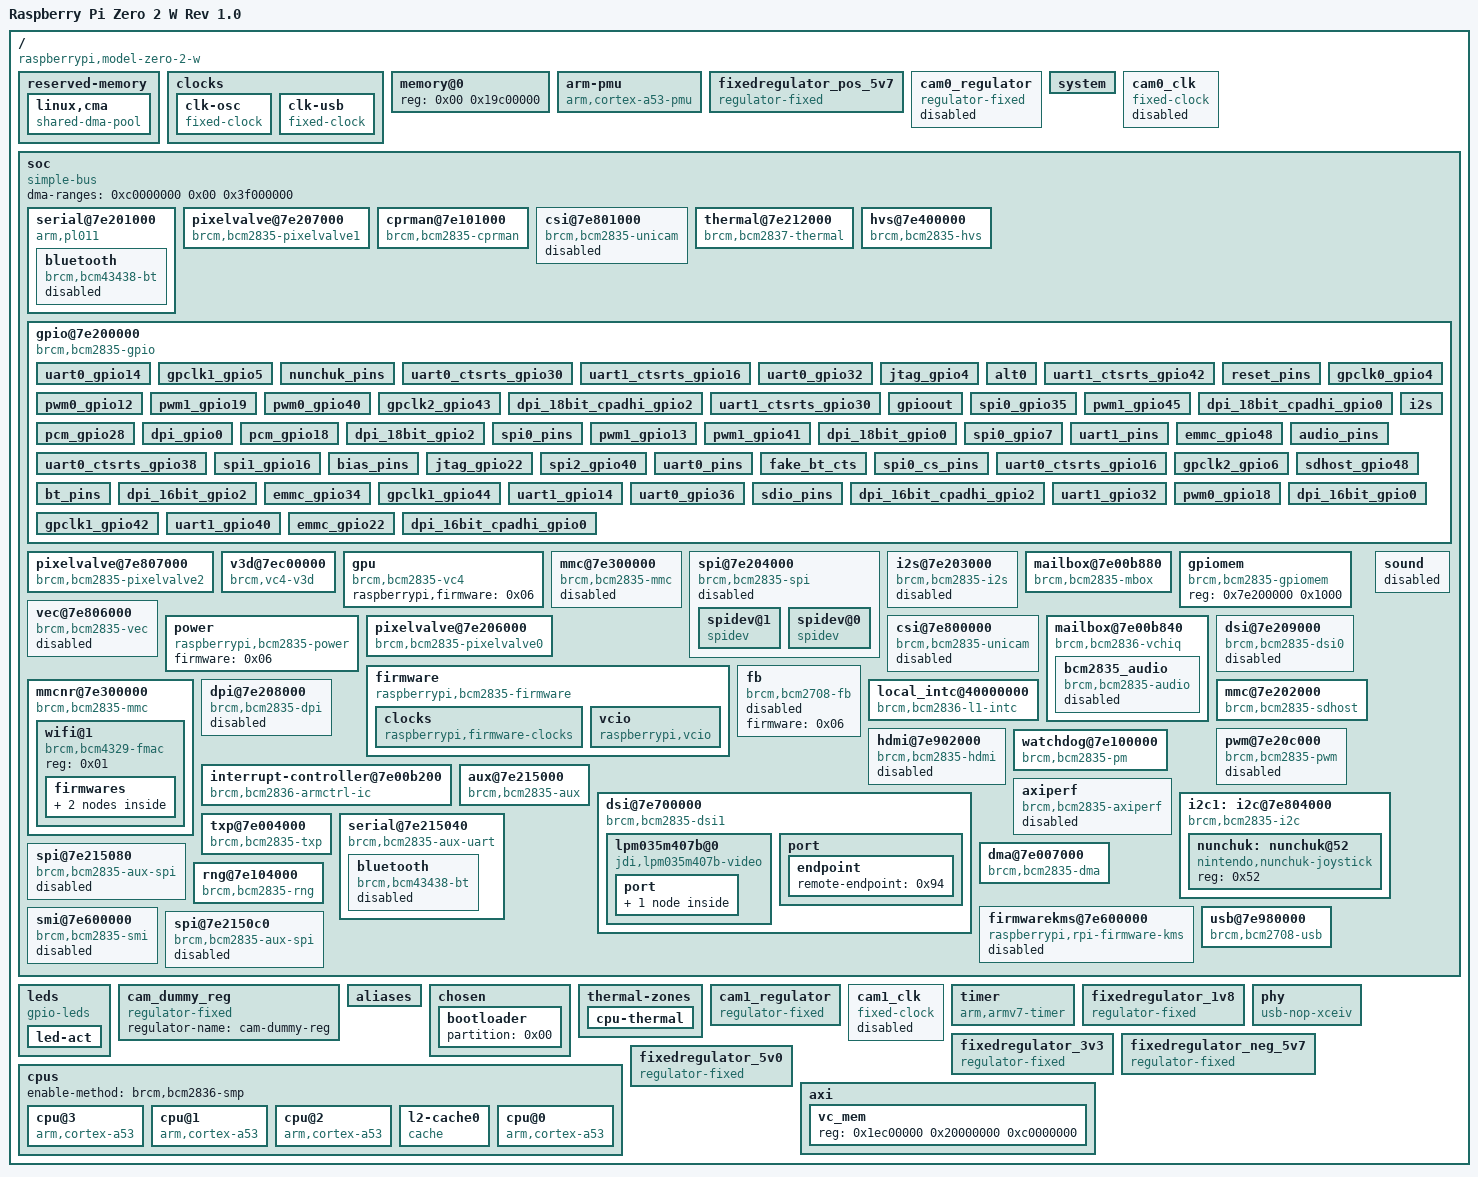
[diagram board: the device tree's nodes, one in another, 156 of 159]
/dts-v1/;

/ {
	compatible = "raspberrypi,model-zero-2-w\0brcm,bcm2837";
	serial-number = "00000000a24858e5";
	model = "Raspberry Pi Zero 2 W Rev 1.0";
	memreserve = <0x19c00000 0x6400000>;
	interrupt-parent = <0x01>;
	#address-cells = <0x01>;
	#size-cells = <0x01>;

	reserved-memory {
		ranges;
		#address-cells = <0x01>;
		#size-cells = <0x01>;
		phandle = <0x34>;

		linux,cma {
			reusable;
			compatible = "shared-dma-pool";
			size = <0x10000000>;
			phandle = <0x35>;
			linux,cma-default;
		};
	};

	clocks {

		clk-osc {
			compatible = "fixed-clock";
			#clock-cells = <0x00>;
			phandle = <0x03>;
			clock-output-names = "osc";
			clock-frequency = <0x124f800>;
		};

		clk-usb {
			compatible = "fixed-clock";
			#clock-cells = <0x00>;
			phandle = <0x18>;
			clock-output-names = "otg";
			clock-frequency = <0x1c9c3800>;
		};
	};

	memory@0 {
		device_type = "memory";
		reg = <0x00 0x19c00000>;
	};

	__overrides__ {
		cam0-led-ctrl;
		sd_overclock = "\0\0\0.brcm,overclock-50:0";
		sdio_overclock = "\0\0\0/brcm,overclock-50:0\0\0\0\00brcm,overclock-50:0";
		sd_pio_limit = "\0\0\0.brcm,pio-limit:0";
		act_led_trigger = "\0\0\03linux,default-trigger";
		audio = "\0\0\0+status";
		sd_debug = "\0\0\0.brcm,debug";
		cam0-pwdn-ctrl;
		cache_line_size;
		cam0-led;
		spi = "\0\0\0(status";
		uart0 = "\0\0\0%status";
		i2s = "\0\0\0'status";
		arm_freq = "\0\0\0!clock-frequency:0\0\0\0\0\"clock-frequency:0\0\0\0\0#clock-frequency:0\0\0\0\0$clock-frequency:0";
		watchdog = "\0\0\0,status";
		krnbt = "\0\0\02status";
		sd_poll_once = "\0\0\0.non-removable?";
		axiperf = "\0\0\01status";
		act_led_activelow = "\0\0\03gpios:8";
		krnbt_baudrate = "\0\0\02max-speed:0";
		sd_force_pio = "\0\0\0.brcm,force-pio?";
		cam0-pwdn;
		uart1 = "\0\0\0&status";
		random = "\0\0\0-status";
		act_led_gpio = "\0\0\03gpios:4";
	};

	arm-pmu {
		compatible = "arm,cortex-a53-pmu\0arm,cortex-a7-pmu";
		interrupt-parent = <0x1a>;
		interrupts = <0x09 0x04>;
	};

	fixedregulator_pos_5v7 {
		compatible = "regulator-fixed";
		enable-active-high;
		gpio = <0x07 0x18 0x00>;
		phandle = <0x96>;
		regulator-min-microvolt = <0x56f9a0>;
		regulator-max-microvolt = <0x56f9a0>;
		regulator-name = "lcm_pos_bias";
	};

	cam0_regulator {
		compatible = "regulator-fixed";
		enable-active-high;
		status = "disabled";
		phandle = <0x8a>;
		regulator-name = "cam0-reg";
	};

	system {
		linux,serial = <0x00 0xa24858e5>;
		linux,revision = <0x902120>;
	};

	__symbols__ {
		uart0_gpio14 = "/soc/gpio@7e200000/uart0_gpio14";
		pwm = "/soc/pwm@7e20c000";
		gpclk1_gpio5 = "/soc/gpio@7e200000/gpclk1_gpio5";
		clk_usb = "/clocks/clk-usb";
		pixelvalve0 = "/soc/pixelvalve@7e206000";
		minibt = "/soc/serial@7e215040/bluetooth";
		uart0_ctsrts_gpio30 = "/soc/gpio@7e200000/uart0_ctsrts_gpio30";
		uart1_ctsrts_gpio16 = "/soc/gpio@7e200000/uart1_ctsrts_gpio16";
		uart0_gpio32 = "/soc/gpio@7e200000/uart0_gpio32";
		intc = "/soc/interrupt-controller@7e00b200";
		spi2 = "/soc/spi@7e2150c0";
		jtag_gpio4 = "/soc/gpio@7e200000/jtag_gpio4";
		dsi1 = "/soc/dsi@7e700000";
		clocks = "/soc/cprman@7e101000";
		alt0 = "/soc/gpio@7e200000/alt0";
		firmwarekms = "/soc/firmwarekms@7e600000";
		smi = "/soc/smi@7e600000";
		uart1_ctsrts_gpio42 = "/soc/gpio@7e200000/uart1_ctsrts_gpio42";
		spi0 = "/soc/spi@7e204000";
		bt = "/soc/serial@7e201000/bluetooth";
		thermal = "/soc/thermal@7e212000";
		vdd_5v0_reg = "/fixedregulator_5v0";
		vchiq = "/soc/mailbox@7e00b840";
		sdhost = "/soc/mmc@7e202000";
		aux = "/soc/aux@7e215000";
		cam0_regulator = "/cam0_regulator";
		gpio = "/soc/gpio@7e200000";
		gpclk0_gpio4 = "/soc/gpio@7e200000/gpclk0_gpio4";
		pwm0_gpio12 = "/soc/gpio@7e200000/pwm0_gpio12";
		pwm1_gpio19 = "/soc/gpio@7e200000/pwm1_gpio19";
		sdhci = "/soc/mmc@7e300000";
		pwm0_gpio40 = "/soc/gpio@7e200000/pwm0_gpio40";
		gpclk2_gpio43 = "/soc/gpio@7e200000/gpclk2_gpio43";
		cam1_reg = "/cam1_regulator";
		dpi = "/soc/dpi@7e208000";
		dpi_18bit_cpadhi_gpio2 = "/soc/gpio@7e200000/dpi_18bit_cpadhi_gpio2";
		v3d = "/soc/v3d@7ec00000";
		audio = "/soc/mailbox@7e00b840/bcm2835_audio";
		vdd_3v3_reg = "/fixedregulator_3v3";
		uart1_ctsrts_gpio30 = "/soc/gpio@7e200000/uart1_ctsrts_gpio30";
		gpioout = "/soc/gpio@7e200000/gpioout";
		dma = "/soc/dma@7e007000";
		spidev1 = "/soc/spi@7e204000/spidev@1";
		mmcnr = "/soc/mmcnr@7e300000";
		spi0_gpio35 = "/soc/gpio@7e200000/spi0_gpio35";
		vc4 = "/soc/gpu";
		firmware_clocks = "/soc/firmware/clocks";
		pwm1_gpio45 = "/soc/gpio@7e200000/pwm1_gpio45";
		cpu3 = "/cpus/cpu@3";
		dpi_18bit_cpadhi_gpio0 = "/soc/gpio@7e200000/dpi_18bit_cpadhi_gpio0";
		cam0_clk = "/cam0_clk";
		pcm_gpio28 = "/soc/gpio@7e200000/pcm_gpio28";
		dpi_gpio0 = "/soc/gpio@7e200000/dpi_gpio0";
		power = "/soc/power";
		soc = "/soc";
		pcm_gpio18 = "/soc/gpio@7e200000/pcm_gpio18";
		leds = "/leds";
		csi1 = "/soc/csi@7e801000";
		i2s_pins = "/soc/gpio@7e200000/i2s";
		cam_dummy_reg = "/cam_dummy_reg";
		firmware = "/soc/firmware";
		cpu1 = "/cpus/cpu@1";
		mmc = "/soc/mmc@7e300000";
		l2 = "/cpus/l2-cache0";
		dpi_18bit_gpio2 = "/soc/gpio@7e200000/dpi_18bit_gpio2";
		usbphy = "/phy";
		pixelvalve1 = "/soc/pixelvalve@7e207000";
		spi = "/soc/spi@7e204000";
		spi0_pins = "/soc/gpio@7e200000/spi0_pins";
		clk_osc = "/clocks/clk-osc";
		uart0 = "/soc/serial@7e201000";
		pwm1_gpio13 = "/soc/gpio@7e200000/pwm1_gpio13";
		rmem = "/reserved-memory";
		cpu_thermal = "/thermal-zones/cpu-thermal";
		fb = "/soc/fb";
		pwm1_gpio41 = "/soc/gpio@7e200000/pwm1_gpio41";
		txp = "/soc/txp@7e004000";
		dpi_18bit_gpio0 = "/soc/gpio@7e200000/dpi_18bit_gpio0";
		spi0_gpio7 = "/soc/gpio@7e200000/spi0_gpio7";
		uart1_pins = "/soc/gpio@7e200000/uart1_pins";
		cma = "/reserved-memory/linux,cma";
		cam1_clk = "/cam1_clk";
		i2s = "/soc/i2s@7e203000";
		emmc_gpio48 = "/soc/gpio@7e200000/emmc_gpio48";
		spi1 = "/soc/spi@7e215080";
		usb = "/soc/usb@7e980000";
		dsi0 = "/soc/dsi@7e209000";
		uart0_ctsrts_gpio38 = "/soc/gpio@7e200000/uart0_ctsrts_gpio38";
		pm = "/soc/watchdog@7e100000";
		audio_pins = "/soc/gpio@7e200000/audio_pins";
		brcmf = "/soc/mmcnr@7e300000/wifi@1";
		spi1_gpio16 = "/soc/gpio@7e200000/spi1_gpio16";
		watchdog = "/soc/watchdog@7e100000";
		jtag_gpio22 = "/soc/gpio@7e200000/jtag_gpio22";
		spi2_gpio40 = "/soc/gpio@7e200000/spi2_gpio40";
		uart0_pins = "/soc/gpio@7e200000/uart0_pins";
		vec = "/soc/vec@7e806000";
		local_intc = "/soc/local_intc@40000000";
		axiperf = "/soc/axiperf";
		spi0_cs_pins = "/soc/gpio@7e200000/spi0_cs_pins";
		sound = "/soc/sound";
		hvs = "/soc/hvs@7e400000";
		uart0_ctsrts_gpio16 = "/soc/gpio@7e200000/uart0_ctsrts_gpio16";
		act_led = "/leds/led-act";
		gpclk2_gpio6 = "/soc/gpio@7e200000/gpclk2_gpio6";
		spidev0 = "/soc/spi@7e204000/spidev@0";
		sdhost_gpio48 = "/soc/gpio@7e200000/sdhost_gpio48";
		bt_pins = "/soc/gpio@7e200000/bt_pins";
		dpi_16bit_gpio2 = "/soc/gpio@7e200000/dpi_16bit_gpio2";
		emmc_gpio34 = "/soc/gpio@7e200000/emmc_gpio34";
		gpclk1_gpio44 = "/soc/gpio@7e200000/gpclk1_gpio44";
		uart1_gpio14 = "/soc/gpio@7e200000/uart1_gpio14";
		uart0_gpio36 = "/soc/gpio@7e200000/uart0_gpio36";
		sdio_pins = "/soc/gpio@7e200000/sdio_pins";
		dpi_16bit_cpadhi_gpio2 = "/soc/gpio@7e200000/dpi_16bit_cpadhi_gpio2";
		cpus = "/cpus";
		cpu2 = "/cpus/cpu@2";
		uart1_gpio32 = "/soc/gpio@7e200000/uart1_gpio32";
		hdmi = "/soc/hdmi@7e902000";
		pixelvalve2 = "/soc/pixelvalve@7e807000";
		pwm0_gpio18 = "/soc/gpio@7e200000/pwm0_gpio18";
		dpi_16bit_gpio0 = "/soc/gpio@7e200000/dpi_16bit_gpio0";
		gpclk1_gpio42 = "/soc/gpio@7e200000/gpclk1_gpio42";
		mailbox = "/soc/mailbox@7e00b880";
		uart1_gpio40 = "/soc/gpio@7e200000/uart1_gpio40";
		emmc_gpio22 = "/soc/gpio@7e200000/emmc_gpio22";
		uart1 = "/soc/serial@7e215040";
		dpi_16bit_cpadhi_gpio0 = "/soc/gpio@7e200000/dpi_16bit_cpadhi_gpio0";
		csi0 = "/soc/csi@7e800000";
		cam0_reg = "/cam_dummy_reg";
		random = "/soc/rng@7e104000";
		cpu0 = "/cpus/cpu@0";
		vcio = "/soc/firmware/vcio";
	};

	cam0_clk {
		compatible = "fixed-clock";
		status = "disabled";
		#clock-cells = <0x00>;
		phandle = <0x8b>;
	};

	soc {
		compatible = "simple-bus";
		ranges = <0x7e000000 0x3f000000 0x1000000 0x40000000 0x40000000 0x1000>;
		#address-cells = <0x01>;
		#size-cells = <0x01>;
		phandle = <0x37>;
		dma-ranges = <0xc0000000 0x00 0x3f000000>;

		serial@7e201000 {
			compatible = "arm,pl011\0arm,primecell";
			clocks = <0x08 0x13 0x08 0x14>;
			clock-names = "uartclk\0apb_pclk";
			status = "okay";
			interrupts = <0x02 0x19>;
			skip-init;
			phandle = <0x25>;
			arm,primecell-periphid = <0x241011>;
			reg = <0x7e201000 0x200>;
			pinctrl-0 = <0x09>;
			cts-event-workaround;
			pinctrl-names = "default";

			bluetooth {
				compatible = "brcm,bcm43438-bt";
				shutdown-gpios = <0x07 0x2a 0x00>;
				max-speed = <0x2dc6c0>;
				status = "disabled";
				phandle = <0x32>;
			};
		};

		pixelvalve@7e207000 {
			compatible = "brcm,bcm2835-pixelvalve1";
			status = "okay";
			interrupts = <0x02 0x0e>;
			phandle = <0x78>;
			reg = <0x7e207000 0x100>;
		};

		cprman@7e101000 {
			compatible = "brcm,bcm2835-cprman";
			clocks = <0x03 0x04 0x00 0x04 0x01 0x04 0x02 0x05 0x00 0x05 0x01 0x05 0x02>;
			firmware = <0x06>;
			#clock-cells = <0x01>;
			phandle = <0x08>;
			claim-clocks = <0x22 0x23 0x0f 0x10>;
			reg = <0x7e101000 0x2000>;
		};

		csi@7e801000 {
			power-domains = <0x13 0x0d>;
			compatible = "brcm,bcm2835-unicam";
			clocks = <0x08 0x2e 0x1b 0x04>;
			clock-names = "lp\0vpu";
			status = "disabled";
			#address-cells = <0x01>;
			interrupts = <0x02 0x07>;
			brcm,num-data-lanes = <0x02>;
			#size-cells = <0x00>;
			#clock-cells = <0x01>;
			phandle = <0x82>;
			reg = <0x7e801000 0x800 0x7e802004 0x04>;
		};

		thermal@7e212000 {
			compatible = "brcm,bcm2837-thermal";
			clocks = <0x08 0x1b>;
			#thermal-sensor-cells = <0x00>;
			status = "okay";
			phandle = <0x02>;
			reg = <0x7e212000 0x08>;
		};

		hvs@7e400000 {
			compatible = "brcm,bcm2835-hvs";
			status = "okay";
			interrupts = <0x02 0x01>;
			phandle = <0x75>;
			reg = <0x7e400000 0x6000>;
		};

		gpio@7e200000 {
			compatible = "brcm,bcm2835-gpio";
			gpio-line-names = "ID_SDA\0ID_SCL\0SDA1\0SCL1\0GPIO_GCLK\0GPIO5\0GPIO6\0SPI_CE1_N\0SPI_CE0_N\0SPI_MISO\0SPI_MOSI\0SPI_SCLK\0GPIO12\0GPIO13\0TXD1\0RXD1\0GPIO16\0GPIO17\0GPIO18\0GPIO19\0GPIO20\0GPIO21\0GPIO22\0GPIO23\0GPIO24\0GPIO25\0GPIO26\0GPIO27\0HDMI_HPD_N\0STATUS_LED_N\0CTS0\0RTS0\0TXD0\0RXD0\0SD1_CLK\0SD1_CMD\0SD1_DATA0\0SD1_DATA1\0SD1_DATA2\0SD1_DATA3\0CAM_GPIO1\0WL_ON\0BT_ON\0WIFI_CLK\0SDA0\0SCL0\0SMPS_SCL\0SMPS_SDA\0SD_CLK_R\0SD_CMD_R\0SD_DATA0_R\0SD_DATA1_R\0SD_DATA2_R\0SD_DATA3_R";
			gpio-controller;
			gpio-ranges = <0x07 0x00 0x00 0x36>;
			#interrupt-cells = <0x02>;
			interrupts = <0x02 0x11 0x02 0x12>;
			phandle = <0x07>;
			reg = <0x7e200000 0xb4>;
			#gpio-cells = <0x02>;
			pinctrl-names = "default";
			interrupt-controller;

			uart0_gpio14 {
				brcm,pins = <0x0e 0x0f>;
				phandle = <0x4c>;
				brcm,function = <0x04>;
			};

			gpclk1_gpio5 {
				brcm,pins = <0x05>;
				phandle = <0x3d>;
				brcm,function = <0x04>;
			};

			nunchuk_pins: nunchuk_pins {
				brcm,pins = <46 47>;
				brcm,pull = <0x00>;
				brcm,function = <5>;
			};

			uart0_ctsrts_gpio30 {
				brcm,pins = <0x1e 0x1f>;
				phandle = <0x4e>;
				brcm,pull = <0x02 0x00>;
				brcm,function = <0x07>;
			};

			uart1_ctsrts_gpio16 {
				brcm,pins = <0x10 0x11>;
				phandle = <0x53>;
				brcm,function = <0x02>;
			};

			uart0_gpio32 {
				brcm,pins = <0x20 0x21>;
				phandle = <0x4f>;
				brcm,pull = <0x00 0x02>;
				brcm,function = <0x07>;
			};

			jtag_gpio4 {
				brcm,pins = <0x04 0x05 0x06 0x0c 0x0d>;
				phandle = <0x59>;
				brcm,function = <0x02>;
			};

			alt0 {
				brcm,pins = <0x04 0x05 0x07 0x08 0x09 0x0a 0x0b>;
				phandle = <0x6a>;
				brcm,function = <0x04>;
			};

			uart1_ctsrts_gpio42 {
				brcm,pins = <0x2a 0x2b>;
				phandle = <0x57>;
				brcm,function = <0x02>;
			};

			reset_pins {
				brcm,pins = <0x16>;
				phandle = <0x99>;
				brcm,pull = <0x00>;
				brcm,function = <0x01>;
			};

			gpclk0_gpio4 {
				brcm,pins = <0x04>;
				phandle = <0x3c>;
				brcm,function = <0x04>;
			};

			pwm0_gpio12 {
				brcm,pins = <0x0c>;
				phandle = <0x5a>;
				brcm,function = <0x04>;
			};

			pwm1_gpio19 {
				brcm,pins = <0x13>;
				phandle = <0x5e>;
				brcm,function = <0x02>;
			};

			pwm0_gpio40 {
				brcm,pins = <0x28>;
				phandle = <0x5c>;
				brcm,function = <0x04>;
			};

			gpclk2_gpio43 {
				brcm,pins = <0x2b>;
				phandle = <0x41>;
				brcm,pull = <0x00>;
				brcm,function = <0x04>;
			};

			dpi_18bit_cpadhi_gpio2 {
				brcm,pins = <0x02 0x03 0x04 0x05 0x06 0x07 0x08 0x09 0x0c 0x0d 0x0e 0x0f 0x10 0x11 0x14 0x15 0x16 0x17 0x18 0x19>;
				phandle = <0x62>;
				brcm,function = <0x06>;
			};

			uart1_ctsrts_gpio30 {
				brcm,pins = <0x1e 0x1f>;
				phandle = <0x55>;
				brcm,function = <0x02>;
			};

			gpioout {
				brcm,pins = <0x06>;
				phandle = <0x69>;
				brcm,function = <0x01>;
			};

			spi0_gpio35 {
				brcm,pins = <0x23 0x24 0x25 0x26 0x27>;
				phandle = <0x49>;
				brcm,function = <0x04>;
			};

			pwm1_gpio45 {
				brcm,pins = <0x2d>;
				phandle = <0x60>;
				brcm,function = <0x04>;
			};

			dpi_18bit_cpadhi_gpio0 {
				brcm,pins = <0x00 0x01 0x02 0x03 0x04 0x05 0x06 0x07 0x08 0x09 0x0c 0x0d 0x0e 0x0f 0x10 0x11 0x14 0x15 0x16 0x17 0x18 0x19>;
				phandle = <0x61>;
				brcm,pull = <0x00>;
				brcm,function = <0x06>;
			};

			pcm_gpio28 {
				brcm,pins = <0x1c 0x1d 0x1e 0x1f>;
				phandle = <0x47>;
				brcm,function = <0x06>;
			};

			dpi_gpio0 {
				brcm,pins = <0x00 0x01 0x02 0x03 0x04 0x05 0x06 0x07 0x08 0x09 0x0a 0x0b 0x0c 0x0d 0x0e 0x0f 0x10 0x11 0x12 0x13 0x14 0x15 0x16 0x17 0x18 0x19 0x1a 0x1b>;
				phandle = <0x39>;
				brcm,function = <0x06>;
			};

			pcm_gpio18 {
				brcm,pins = <0x12 0x13 0x14 0x15>;
				phandle = <0x46>;
				brcm,function = <0x04>;
			};

			dpi_18bit_gpio2 {
				brcm,pins = <0x02 0x03 0x04 0x05 0x06 0x07 0x08 0x09 0x0a 0x0b 0x0c 0x0d 0x0e 0x0f 0x10 0x11 0x12 0x13 0x14 0x15>;
				phandle = <0x64>;
				brcm,function = <0x06>;
			};

			spi0_pins {
				brcm,pins = <0x09 0x0a 0x0b>;
				phandle = <0x0e>;
				brcm,function = <0x04>;
			};

			pwm1_gpio13 {
				brcm,pins = <0x0d>;
				phandle = <0x5d>;
				brcm,function = <0x04>;
			};

			pwm1_gpio41 {
				brcm,pins = <0x29>;
				phandle = <0x5f>;
				brcm,function = <0x04>;
			};

			dpi_18bit_gpio0 {
				brcm,pins = <0x00 0x01 0x02 0x03 0x04 0x05 0x06 0x07 0x08 0x09 0x0a 0x0b 0x0c 0x0d 0x0e 0x0f 0x10 0x11 0x12 0x13 0x14 0x15>;
				phandle = <0x63>;
				brcm,function = <0x06>;
			};

			spi0_gpio7 {
				brcm,pins = <0x07 0x08 0x09 0x0a 0x0b>;
				phandle = <0x48>;
				brcm,function = <0x04>;
			};

			uart1_pins {
				brcm,pins = <0x20 0x21>;
				phandle = <0x15>;
				brcm,pull = <0x00 0x02>;
				brcm,function = <0x02>;
			};

			i2s {
				brcm,pins = <0x12 0x13 0x14 0x15>;
				phandle = <0x0d>;
				brcm,function = <0x04>;
			};

			emmc_gpio48 {
				brcm,pins = <0x30 0x31 0x32 0x33 0x34 0x35>;
				phandle = <0x16>;
				brcm,function = <0x07>;
			};

			uart0_ctsrts_gpio38 {
				brcm,pins = <0x26 0x27>;
				phandle = <0x51>;
				brcm,function = <0x06>;
			};

			audio_pins {
				brcm,pins;
				phandle = <0x1f>;
				brcm,function;
			};

			spi1_gpio16 {
				brcm,pins = <0x10 0x11 0x12 0x13 0x14 0x15>;
				phandle = <0x4a>;
				brcm,function = <0x03>;
			};

			bias_pins {
				brcm,pins = <0x18 0x19>;
				phandle = <0x9a>;
				brcm,pull = <0x00>;
				brcm,function = <0x01>;
			};

			jtag_gpio22 {
				brcm,pins = <0x16 0x17 0x18 0x19 0x1a 0x1b>;
				phandle = <0x45>;
				brcm,function = <0x03>;
			};

			spi2_gpio40 {
				brcm,pins = <0x28 0x29 0x2a 0x2b 0x2c 0x2d>;
				phandle = <0x4b>;
				brcm,function = <0x03>;
			};

			uart0_pins {
				brcm,pins;
				phandle = <0x09>;
				brcm,pull;
				brcm,function;
			};

			fake_bt_cts {
				brcm,pins = <0x1f>;
				phandle = <0x90>;
				brcm,function = <0x01>;
			};

			spi0_cs_pins {
				brcm,pins = <0x08 0x07>;
				phandle = <0x0f>;
				brcm,function = <0x01>;
			};

			uart0_ctsrts_gpio16 {
				brcm,pins = <0x10 0x11>;
				phandle = <0x4d>;
				brcm,function = <0x07>;
			};

			gpclk2_gpio6 {
				brcm,pins = <0x06>;
				phandle = <0x40>;
				brcm,function = <0x04>;
			};

			sdhost_gpio48 {
				brcm,pins = <0x30 0x31 0x32 0x33 0x34 0x35>;
				phandle = <0x0c>;
				brcm,function = <0x04>;
			};

			bt_pins {
				brcm,pins = <0x2b>;
				phandle = <0x0a>;
				brcm,pull = <0x00>;
				brcm,function = <0x04>;
			};

			dpi_16bit_gpio2 {
				brcm,pins = <0x02 0x03 0x04 0x05 0x06 0x07 0x08 0x09 0x0a 0x0b 0x0c 0x0d 0x0e 0x0f 0x10 0x11 0x12 0x13>;
				phandle = <0x66>;
				brcm,function = <0x06>;
			};

			emmc_gpio34 {
				brcm,pins = <0x22 0x23 0x24 0x25 0x26 0x27>;
				phandle = <0x3b>;
				brcm,pull = <0x00 0x02 0x02 0x02 0x02 0x02>;
				brcm,function = <0x07>;
			};

			gpclk1_gpio44 {
				brcm,pins = <0x2c>;
				phandle = <0x3f>;
				brcm,function = <0x04>;
			};

			uart1_gpio14 {
				brcm,pins = <0x0e 0x0f>;
				phandle = <0x52>;
				brcm,function = <0x02>;
			};

			uart0_gpio36 {
				brcm,pins = <0x24 0x25>;
				phandle = <0x50>;
				brcm,function = <0x06>;
			};

			sdio_pins {
				brcm,pins = <0x22 0x23 0x24 0x25 0x26 0x27>;
				phandle = <0x1d>;
				brcm,pull = <0x00 0x02 0x02 0x02 0x02 0x02>;
				brcm,function = <0x07>;
			};

			dpi_16bit_cpadhi_gpio2 {
				brcm,pins = <0x02 0x03 0x04 0x05 0x06 0x07 0x08 0x0c 0x0d 0x0e 0x0f 0x10 0x11 0x14 0x15 0x16 0x17 0x18>;
				phandle = <0x68>;
				brcm,function = <0x06>;
			};

			uart1_gpio32 {
				brcm,pins = <0x20 0x21>;
				phandle = <0x54>;
				brcm,function = <0x02>;
			};

			pwm0_gpio18 {
				brcm,pins = <0x12>;
				phandle = <0x5b>;
				brcm,function = <0x02>;
			};

			dpi_16bit_gpio0 {
				brcm,pins = <0x00 0x01 0x02 0x03 0x04 0x05 0x06 0x07 0x08 0x09 0x0a 0x0b 0x0c 0x0d 0x0e 0x0f 0x10 0x11 0x12 0x13>;
				phandle = <0x65>;
				brcm,function = <0x06>;
			};

			gpclk1_gpio42 {
				brcm,pins = <0x2a>;
				phandle = <0x3e>;
				brcm,function = <0x04>;
			};

			uart1_gpio40 {
				brcm,pins = <0x28 0x29>;
				phandle = <0x56>;
				brcm,function = <0x02>;
			};

			emmc_gpio22 {
				brcm,pins = <0x16 0x17 0x18 0x19 0x1a 0x1b>;
				phandle = <0x3a>;
				brcm,function = <0x07>;
			};

			dpi_16bit_cpadhi_gpio0 {
				brcm,pins = <0x00 0x01 0x02 0x03 0x04 0x05 0x06 0x07 0x08 0x0c 0x0d 0x0e 0x0f 0x10 0x11 0x14 0x15 0x16 0x17 0x18>;
				phandle = <0x67>;
				brcm,function = <0x06>;
			};
		};

		pixelvalve@7e807000 {
			compatible = "brcm,bcm2835-pixelvalve2";
			status = "okay";
			interrupts = <0x02 0x0a>;
			phandle = <0x7a>;
			reg = <0x7e807000 0x100>;
		};

		v3d@7ec00000 {
			power-domains = <0x13 0x0a>;
			compatible = "brcm,vc4-v3d";
			status = "okay";
			interrupts = <0x01 0x0a>;
			phandle = <0x7c>;
			reg = <0x7ec00000 0x1000>;
		};

		gpu {
			compatible = "brcm,bcm2835-vc4";
			status = "okay";
			phandle = <0x7d>;
			raspberrypi,firmware = <0x06>;
		};

		mmc@7e300000 {
			compatible = "brcm,bcm2835-mmc\0brcm,bcm2835-sdhci";
			clocks = <0x08 0x1c>;
			status = "disabled";
			interrupts = <0x02 0x1e>;
			brcm,overclock-50 = <0x00>;
			bus-width = <0x04>;
			dma-names = "rx-tx";
			phandle = <0x2f>;
			reg = <0x7e300000 0x100>;
			pinctrl-0 = <0x16>;
			dmas = <0x0b 0x0b>;
			pinctrl-names = "default";
		};

		spi@7e204000 {
			compatible = "brcm,bcm2835-spi";
			clocks = <0x08 0x14>;
			status = "disabled";
			#address-cells = <0x01>;
			interrupts = <0x02 0x16>;
			cs-gpios = <0x07 0x08 0x01 0x07 0x07 0x01>;
			#size-cells = <0x00>;
			dma-names = "tx\0rx";
			phandle = <0x28>;
			reg = <0x7e204000 0x200>;
			pinctrl-0 = <0x0e 0x0f>;
			dmas = <0x0b 0x06 0x0b 0x07>;
			pinctrl-names = "default";

			spidev@1 {
				compatible = "spidev";
				#address-cells = <0x01>;
				#size-cells = <0x00>;
				phandle = <0x6d>;
				reg = <0x01>;
				spi-max-frequency = <0x7735940>;
			};

			spidev@0 {
				compatible = "spidev";
				#address-cells = <0x01>;
				#size-cells = <0x00>;
				phandle = <0x6c>;
				reg = <0x00>;
				spi-max-frequency = <0x7735940>;
			};
		};

		i2s@7e203000 {
			compatible = "brcm,bcm2835-i2s";
			clocks = <0x08 0x1f>;
			#sound-dai-cells = <0x00>;
			status = "disabled";
			dma-names = "tx\0rx";
			phandle = <0x27>;
			reg = <0x7e203000 0x24>;
			pinctrl-0 = <0x0d>;
			dmas = <0x0b 0x02 0x0b 0x03>;
			pinctrl-names = "default";
		};

		mailbox@7e00b880 {
			compatible = "brcm,bcm2835-mbox";
			#mbox-cells = <0x00>;
			interrupts = <0x00 0x01>;
			phandle = <0x1e>;
			reg = <0x7e00b880 0x40>;
		};

		gpiomem {
			compatible = "brcm,bcm2835-gpiomem";
			reg = <0x7e200000 0x1000>;
		};

		vec@7e806000 {
			power-domains = <0x13 0x07>;
			compatible = "brcm,bcm2835-vec";
			clocks = <0x1b 0x0f>;
			status = "disabled";
			interrupts = <0x02 0x1b>;
			phandle = <0x79>;
			reg = <0x7e806000 0x1000>;
		};

		power {
			compatible = "raspberrypi,bcm2835-power";
			firmware = <0x06>;
			phandle = <0x13>;
			#power-domain-cells = <0x01>;
		};

		pixelvalve@7e206000 {
			compatible = "brcm,bcm2835-pixelvalve0";
			status = "okay";
			interrupts = <0x02 0x0d>;
			phandle = <0x77>;
			reg = <0x7e206000 0x100>;
		};

		csi@7e800000 {
			power-domains = <0x13 0x0c>;
			compatible = "brcm,bcm2835-unicam";
			clocks = <0x08 0x2d 0x1b 0x04>;
			clock-names = "lp\0vpu";
			status = "disabled";
			#address-cells = <0x01>;
			interrupts = <0x02 0x06>;
			#size-cells = <0x00>;
			#clock-cells = <0x01>;
			phandle = <0x81>;
			reg = <0x7e800000 0x800 0x7e802000 0x04>;
		};

		mailbox@7e00b840 {
			compatible = "brcm,bcm2836-vchiq\0brcm,bcm2835-vchiq";
			interrupts = <0x00 0x02>;
			phandle = <0x84>;
			reg = <0x7e00b840 0x3c>;

			bcm2835_audio {
				brcm,pwm-channels = <0x08>;
				compatible = "brcm,bcm2835-audio";
				brcm,disable-headphones = <0x01>;
				brcm,disable-hdmi;
				status = "disabled";
				brcm,firmware = <0x06>;
				phandle = <0x2b>;
				pinctrl-0 = <0x1f>;
				pinctrl-names = "default";
			};
		};

		firmware {
			compatible = "raspberrypi,bcm2835-firmware\0simple-mfd";
			#address-cells = <0x01>;
			mboxes = <0x1e>;
			#size-cells = <0x01>;
			phandle = <0x06>;
			dma-ranges;

			clocks {
				compatible = "raspberrypi,firmware-clocks";
				#clock-cells = <0x01>;
				phandle = <0x1b>;
			};

			vcio {
				compatible = "raspberrypi,vcio";
				phandle = <0x83>;
			};
		};

		dsi@7e209000 {
			power-domains = <0x13 0x11>;
			compatible = "brcm,bcm2835-dsi0";
			clocks = <0x08 0x20 0x08 0x2f 0x08 0x31>;
			clock-names = "phy\0escape\0pixel";
			status = "disabled";
			#address-cells = <0x01>;
			interrupts = <0x02 0x04>;
			#size-cells = <0x00>;
			#clock-cells = <0x01>;
			phandle = <0x04>;
			reg = <0x7e209000 0x78>;
			clock-output-names = "dsi0_byte\0dsi0_ddr2\0dsi0_ddr";
		};

		mmcnr@7e300000 {
			compatible = "brcm,bcm2835-mmc\0brcm,bcm2835-sdhci";
			clocks = <0x08 0x1c>;
			status = "okay";
			#address-cells = <0x01>;
			interrupts = <0x02 0x1e>;
			brcm,overclock-50 = <0x00>;
			bus-width = <0x04>;
			#size-cells = <0x00>;
			dma-names = "rx-tx";
			phandle = <0x30>;
			reg = <0x7e300000 0x100>;
			pinctrl-0 = <0x1d>;
			dmas = <0x0b 0x0b>;
			non-removable;
			pinctrl-names = "default";

			wifi@1 {
				compatible = "brcm,bcm4329-fmac";
				phandle = <0x7e>;
				reg = <0x01>;

				firmwares {

					fw_43436p {
						revmask = <0x04>;
						fw_base = "brcm/brcmfmac43436-sdio";
						chipid = <0xa9a6>;
					};

					fw_43436s {
						revmask = <0x02>;
						fw_base = "brcm/brcmfmac43436s-sdio";
						chipid = <0xa9a6>;
					};
				};
			};
		};

		fb {
			compatible = "brcm,bcm2708-fb";
			firmware = <0x06>;
			status = "disabled";
			phandle = <0x85>;
		};

		local_intc@40000000 {
			compatible = "brcm,bcm2836-l1-intc";
			#interrupt-cells = <0x02>;
			interrupt-parent = <0x1a>;
			phandle = <0x1a>;
			reg = <0x40000000 0x100>;
			interrupt-controller;
		};

		dpi@7e208000 {
			compatible = "brcm,bcm2835-dpi";
			clocks = <0x08 0x14 0x08 0x2c>;
			clock-names = "core\0pixel";
			status = "disabled";
			#address-cells = <0x01>;
			#size-cells = <0x00>;
			phandle = <0x70>;
			reg = <0x7e208000 0x8c>;
		};

		mmc@7e202000 {
			compatible = "brcm,bcm2835-sdhost";
			clocks = <0x08 0x14>;
			brcm,pio-limit = <0x01>;
			firmware = <0x06>;
			status = "okay";
			interrupts = <0x02 0x18>;
			brcm,overclock-50 = <0x00>;
			bus-width = <0x04>;
			dma-names = "rx-tx";
			phandle = <0x2e>;
			reg = <0x7e202000 0x100>;
			pinctrl-0 = <0x0c>;
			dmas = <0x0b 0x2000000d>;
			pinctrl-names = "default";
		};

		hdmi@7e902000 {
			power-domains = <0x13 0x05>;
			compatible = "brcm,bcm2835-hdmi";
			clocks = <0x1b 0x09 0x1b 0x0d>;
			reg-names = "hdmi\0hd";
			clock-names = "pixel\0hdmi";
			ddc = <0x1c>;
			status = "disabled";
			interrupts = <0x02 0x08 0x02 0x09>;
			dma-names = "audio-rx";
			phandle = <0x7b>;
			hpd-gpios = <0x07 0x1c 0x01>;
			reg = <0x7e902000 0x600 0x7e808000 0x100>;
			dmas;
		};

		pwm@7e20c000 {
			compatible = "brcm,bcm2835-pwm";
			clocks = <0x08 0x1e>;
			status = "disabled";
			assigned-clock-rates = <0x989680>;
			assigned-clocks = <0x08 0x1e>;
			phandle = <0x74>;
			reg = <0x7e20c000 0x28>;
			#pwm-cells = <0x02>;
		};

		watchdog@7e100000 {
			compatible = "brcm,bcm2835-pm\0brcm,bcm2835-pm-wdt";
			clocks = <0x08 0x15 0x08 0x1d 0x08 0x17 0x08 0x16>;
			#reset-cells = <0x01>;
			clock-names = "v3d\0peri_image\0h264\0isp";
			system-power-controller;
			phandle = <0x2c>;
			reg = <0x7e100000 0x114 0x7e00a000 0x24>;
			#power-domain-cells = <0x01>;
		};

		interrupt-controller@7e00b200 {
			compatible = "brcm,bcm2836-armctrl-ic";
			#interrupt-cells = <0x02>;
			interrupt-parent = <0x1a>;
			interrupts = <0x08 0x04>;
			phandle = <0x01>;
			reg = <0x7e00b200 0x200>;
			interrupt-controller;
		};

		aux@7e215000 {
			compatible = "brcm,bcm2835-aux";
			clocks = <0x08 0x14>;
			#clock-cells = <0x01>;
			phandle = <0x14>;
			reg = <0x7e215000 0x08>;
		};

		dsi@7e700000 {
			power-domains = <0x13 0x12>;
			compatible = "brcm,bcm2835-dsi1";
			clocks = <0x08 0x23 0x08 0x30 0x08 0x32>;
			clock-names = "phy\0escape\0pixel";
			status = "okay";
			#address-cells = <0x01>;
			interrupts = <0x02 0x0c>;
			#size-cells = <0x00>;
			#clock-cells = <0x01>;
			phandle = <0x05>;
			reg = <0x7e700000 0x8c>;
			clock-output-names = "dsi1_byte\0dsi1_ddr2\0dsi1_ddr";

			lpm035m407b@0 {
				video-flags = <0xc01>;
				compatible = "jdi,lpm035m407b-video";
				vddi-supply = <0x95>;
				status = "okay";
				reset-gpios = <0x07 0x16 0x00>;
				panel-mode = <0x22ab0 0x5a0 0x5be 0x5c0 0x5de 0x640 0x64a 0x64c 0x656 0x3c 0x42 0x00>;
				phandle = <0x9c>;
				debug-on;
				reg = <0x00>;
				avdd-supply = <0x96>;
				panel-orient = <0x02>;
				on-cmds = [02 ff 10 02 fb 01 05 2a 00 00 05 9f 05 2b 00 00 06 3f 02 35 00 02 ba 07 02 bb 13 02 e5 00 02 ff 26 02 fb 01 02 02 c0 02 03 00 02 ff 25 02 fb 01 02 62 60 02 65 00 02 66 07 02 67 56 02 ff d0 02 fb 01 02 05 88 02 ff 10 02 fb 01 02 c0 00 04 3b 03 0a 0a 02 ff 10 02 fb 01];
				avee-supply = <0x97>;

				port {

					endpoint {
						remote-endpoint = <0x98>;
						phandle = <0x94>;
					};
				};
			};

			port {

				endpoint {
					remote-endpoint = <0x94>;
					phandle = <0x98>;
				};
			};
		};

		axiperf {
			compatible = "brcm,bcm2835-axiperf";
			firmware = <0x06>;
			status = "disabled";
			phandle = <0x31>;
			reg = <0x7e009800 0x100 0x7ee08000 0x100>;
		};

		sound {
			status = "disabled";
			phandle = <0x86>;
		};

		i2c1: i2c@7e804000 {
			compatible = "brcm,bcm2835-i2c";
			clocks = <0x08 0x14>;
			status = "okay";
			#address-cells = <0x01>;
			interrupts = <0x02 0x15>;
			#size-cells = <0x00>;
			phandle = <0x10>;
			reg = <0x7e804000 0x200>;
			clock-frequency = <0x186a0>;
			pinctrl-names = "default";
			pinctrl-0 = <&nunchuk_pins>;

			nunchuk: nunchuk@52 {
				compatible = "nintendo,nunchuk-joystick";
				reg = <0x52>;
			};
		};

		txp@7e004000 {
			compatible = "brcm,bcm2835-txp";
			status = "okay";
			interrupts = <0x01 0x0b>;
			phandle = <0x38>;
			reg = <0x7e004000 0x20>;
		};

		serial@7e215040 {
			compatible = "brcm,bcm2835-aux-uart";
			clocks = <0x14 0x00>;
			status = "okay";
			interrupts = <0x01 0x1d>;
			skip-init;
			phandle = <0x26>;
			reg = <0x7e215040 0x40>;
			pinctrl-0 = <0x15 0x0a 0x90>;
			pinctrl-names = "default";

			bluetooth {
				compatible = "brcm,bcm43438-bt";
				shutdown-gpios = <0x07 0x2a 0x00>;
				max-speed = "\0\a\b";
				status = "disabled";
				phandle = <0x71>;
			};
		};

		dma@7e007000 {
			#dma-cells = <0x01>;
			compatible = "brcm,bcm2835-dma";
			brcm,dma-channel-mask = <0x7f35>;
			interrupts = <0x01 0x10 0x01 0x11 0x01 0x12 0x01 0x13 0x01 0x14 0x01 0x15 0x01 0x16 0x01 0x17 0x01 0x18 0x01 0x19 0x01 0x1a 0x01 0x1b 0x01 0x1b 0x01 0x1b 0x01 0x1b 0x01 0x1c>;
			phandle = <0x0b>;
			reg = <0x7e007000 0xf00>;
			interrupt-names = "dma0\0dma1\0dma2\0dma3\0dma4\0dma5\0dma6\0dma7\0dma8\0dma9\0dma10\0dma11\0dma12\0dma13\0dma14\0dma-shared-all";
		};

		spi@7e215080 {
			compatible = "brcm,bcm2835-aux-spi";
			clocks = <0x14 0x01>;
			status = "disabled";
			#address-cells = <0x01>;
			interrupts = <0x01 0x1d>;
			#size-cells = <0x00>;
			phandle = <0x72>;
			reg = <0x7e215080 0x40>;
		};

		firmwarekms@7e600000 {
			compatible = "raspberrypi,rpi-firmware-kms";
			status = "disabled";
			interrupts = <0x02 0x10>;
			brcm,firmware = <0x06>;
			phandle = <0x7f>;
			reg = <0x7e600000 0x100>;
		};

		rng@7e104000 {
			compatible = "brcm,bcm2835-rng";
			interrupts = <0x02 0x1d>;
			phandle = <0x2d>;
			reg = <0x7e104000 0x10>;
		};

		usb@7e980000 {
			power-domains = <0x13 0x06>;
			compatible = "brcm,bcm2708-usb";
			clocks = <0x18>;
			clock-names = "otg";
			phy-names = "usb2-phy";
			#address-cells = <0x01>;
			interrupts = <0x01 0x09 0x02 0x00>;
			#size-cells = <0x00>;
			phandle = <0x76>;
			phys = <0x19>;
			reg = <0x7e980000 0x10000 0x7e006000 0x1000>;
			interrupt-names = "usb\0soft";
		};

		smi@7e600000 {
			compatible = "brcm,bcm2835-smi";
			clocks = <0x08 0x2a>;
			status = "disabled";
			interrupts = <0x02 0x10>;
			assigned-clock-rates = <0x7735940>;
			dma-names = "rx-tx";
			assigned-clocks = <0x08 0x2a>;
			phandle = <0x80>;
			reg = <0x7e600000 0x100>;
			dmas = <0x0b 0x04>;
		};

		spi@7e2150c0 {
			compatible = "brcm,bcm2835-aux-spi";
			clocks = <0x14 0x02>;
			status = "disabled";
			#address-cells = <0x01>;
			interrupts = <0x01 0x1d>;
			#size-cells = <0x00>;
			phandle = <0x73>;
			reg = <0x7e2150c0 0x40>;
		};
	};

	leds {
		compatible = "gpio-leds";
		phandle = <0x8d>;

		led-act {
			gpios = <0x07 0x1d 0x01>;
			label = "led0";
			phandle = <0x33>;
			default-state = "keep";
			linux,default-trigger = "actpwr";
		};
	};

	cam_dummy_reg {
		compatible = "regulator-fixed";
		status = "okay";
		phandle = <0x8c>;
		regulator-name = "cam-dummy-reg";
	};

	aliases {
		intc = "/soc/interrupt-controller@7e00b200";
		spi2 = "/soc/spi@7e2150c0";
		spi0 = "/soc/spi@7e204000";
		thermal = "/soc/thermal@7e212000";
		sdhost = "/soc/mmc@7e202000";
		aux = "/soc/aux@7e215000";
		gpio = "/soc/gpio@7e200000";
		mmc1 = "/soc/mmcnr@7e300000";
		audio = "/soc/mailbox@7e00b840/bcm2835_audio";
		dma = "/soc/dma@7e007000";
		soc = "/soc";
		leds = "/leds";
		mmc = "/soc/mmc@7e300000";
		serial1 = "/soc/serial@7e215040";
		uart0 = "/soc/serial@7e201000";
		fb = "/soc/fb";
		i2s = "/soc/i2s@7e203000";
		spi1 = "/soc/spi@7e215080";
		usb = "/soc/usb@7e980000";
		watchdog = "/soc/watchdog@7e100000";
		axiperf = "/soc/axiperf";
		mmc0 = "/soc/mmc@7e202000";
		sound = "/soc/sound";
		mailbox = "/soc/mailbox@7e00b880";
		uart1 = "/soc/serial@7e215040";
		random = "/soc/rng@7e104000";
		serial0 = "/soc/serial@7e201000";
	};

	chosen {
		bootargs = "coherent_pool=1M 8250.nr_uarts=1 snd_bcm2835.enable_compat_alsa=0 snd_bcm2835.enable_hdmi=1  smsc95xx.macaddr=B8:27:EB:48:58:E5 vc_mem.mem_base=0x1ec00000 vc_mem.mem_size=0x20000000  root=/dev/mmcblk0p2 rootwait console=tty1 console=ttyAMA0,115200";
		rpi-boardrev-ext = <0x00>;
		kaslr-seed = <0x2b6d21a2 0xbbfb4d60>;

		bootloader {
			partition = <0x00>;
		};
	};

	thermal-zones {

		cpu-thermal {
			thermal-sensors = <0x02>;
			polling-delay = <0x3e8>;
			polling-delay-passive = <0x00>;
			coefficients = <0xfffffde6 0x64960>;
			phandle = <0x36>;
		};
	};

	cam1_regulator {
		compatible = "regulator-fixed";
		enable-active-high;
		gpio = <0x07 0x28 0x00>;
		status = "okay";
		phandle = <0x88>;
		regulator-name = "cam1-reg";
	};

	cam1_clk {
		compatible = "fixed-clock";
		status = "disabled";
		#clock-cells = <0x00>;
		phandle = <0x89>;
	};

	timer {
		compatible = "arm,armv7-timer";
		always-on;
		interrupt-parent = <0x1a>;
		interrupts = <0x00 0x04 0x01 0x04 0x03 0x04 0x02 0x04>;
	};

	fixedregulator_1v8 {
		compatible = "regulator-fixed";
		phandle = <0x95>;
		regulator-min-microvolt = <0x1b7740>;
		regulator-max-microvolt = <0x1b7740>;
		regulator-always-on;
		regulator-name = "1v8";
	};

	phy {
		compatible = "usb-nop-xceiv";
		phandle = <0x19>;
		#phy-cells = <0x00>;
	};

	fixedregulator_3v3 {
		compatible = "regulator-fixed";
		phandle = <0x8e>;
		regulator-min-microvolt = <0x325aa0>;
		regulator-max-microvolt = <0x325aa0>;
		regulator-always-on;
		regulator-name = "3v3";
	};

	cpus {
		enable-method = "brcm,bcm2836-smp";
		#address-cells = <0x01>;
		#size-cells = <0x00>;
		phandle = <0x87>;

		cpu@3 {
			compatible = "arm,cortex-a53";
			cpu-release-addr = <0x00 0xf0>;
			device_type = "cpu";
			i-cache-line-size = <0x40>;
			next-level-cache = <0x20>;
			enable-method = "spin-table";
			phandle = <0x24>;
			reg = <0x03>;
			clock-frequency = <0x3b9aca00>;
			d-cache-size = <0x8000>;
			i-cache-size = <0x8000>;
			d-cache-sets = <0x80>;
			i-cache-sets = <0x100>;
			d-cache-line-size = <0x40>;
		};

		cpu@1 {
			compatible = "arm,cortex-a53";
			cpu-release-addr = <0x00 0xe0>;
			device_type = "cpu";
			i-cache-line-size = <0x40>;
			next-level-cache = <0x20>;
			enable-method = "spin-table";
			phandle = <0x22>;
			reg = <0x01>;
			clock-frequency = <0x3b9aca00>;
			d-cache-size = <0x8000>;
			i-cache-size = <0x8000>;
			d-cache-sets = <0x80>;
			i-cache-sets = <0x100>;
			d-cache-line-size = <0x40>;
		};

		cpu@2 {
			compatible = "arm,cortex-a53";
			cpu-release-addr = <0x00 0xe8>;
			device_type = "cpu";
			i-cache-line-size = <0x40>;
			next-level-cache = <0x20>;
			enable-method = "spin-table";
			phandle = <0x23>;
			reg = <0x02>;
			clock-frequency = <0x3b9aca00>;
			d-cache-size = <0x8000>;
			i-cache-size = <0x8000>;
			d-cache-sets = <0x80>;
			i-cache-sets = <0x100>;
			d-cache-line-size = <0x40>;
		};

		l2-cache0 {
			compatible = "cache";
			cache-level = <0x02>;
			cache-line-size = <0x40>;
			phandle = <0x20>;
			cache-size = <0x80000>;
			cache-sets = <0x200>;
		};

		cpu@0 {
			compatible = "arm,cortex-a53";
			cpu-release-addr = <0x00 0xd8>;
			device_type = "cpu";
			i-cache-line-size = <0x40>;
			next-level-cache = <0x20>;
			enable-method = "spin-table";
			phandle = <0x21>;
			reg = <0x00>;
			clock-frequency = <0x3b9aca00>;
			d-cache-size = <0x8000>;
			i-cache-size = <0x8000>;
			d-cache-sets = <0x80>;
			i-cache-sets = <0x100>;
			d-cache-line-size = <0x40>;
		};
	};

	fixedregulator_neg_5v7 {
		compatible = "regulator-fixed";
		enable-active-high;
		gpio = <0x07 0x19 0x00>;
		phandle = <0x97>;
		regulator-min-microvolt = <0x56f9a0>;
		regulator-max-microvolt = <0x56f9a0>;
		regulator-name = "lcm_neg_bias";
	};

	fixedregulator_5v0 {
		compatible = "regulator-fixed";
		phandle = <0x8f>;
		regulator-min-microvolt = <0x4c4b40>;
		regulator-max-microvolt = <0x4c4b40>;
		regulator-always-on;
		regulator-name = "5v0";
	};

	axi {

		vc_mem {
			reg = <0x1ec00000 0x20000000 0xc0000000>;
		};
	};
};

